# DMPAC0_SDE_0_PAR_PAR_SDE_S_VBUSP_MEM_MMRRAM_VBUSP_MMR_RAM register map
Vendor: Texas Instruments
Peripheral module from a debugger description file (folder J721S2).
Registers are 32-bit, read-only, reset 0x0 unless marked. A register's access mark holds for its fields unless they carry their own. Offsets are as the file gives them; lines under a group give offsets from that group; [hi:lo] are bit positions; {n}, {i} and the like mark numbered series; 'fields as' and 'values as' point back to an identical list; <NAME> marks a mode.

## DMPAC0_SDE_0_PAR_PAR_SDE_S_VBUSP_MEM_MMRRAM_VBUSP_MMR_RAM
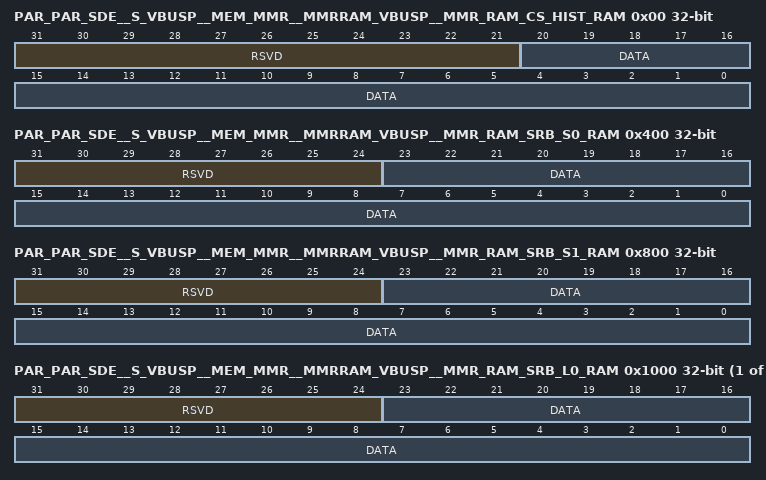
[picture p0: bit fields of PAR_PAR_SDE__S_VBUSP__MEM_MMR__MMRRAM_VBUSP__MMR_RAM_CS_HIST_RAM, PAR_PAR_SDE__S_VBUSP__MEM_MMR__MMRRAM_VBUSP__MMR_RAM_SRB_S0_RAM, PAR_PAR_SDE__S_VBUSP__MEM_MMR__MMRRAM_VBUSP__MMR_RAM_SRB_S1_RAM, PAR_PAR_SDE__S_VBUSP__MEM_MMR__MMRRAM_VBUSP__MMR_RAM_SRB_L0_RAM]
0x00 PAR_PAR_SDE__S_VBUSP__MEM_MMR__MMRRAM_VBUSP__MMR_RAM_CS_HIST_RAM — cs_hist_ram diagnostic read only port, vbusp will stall until RAM is available for read
  [31:21] RSVD — Always read as 0. Writes have no effect.
  [20:0] DATA — Data read from RAM
0x400 PAR_PAR_SDE__S_VBUSP__MEM_MMR__MMRRAM_VBUSP__MMR_RAM_SRB_S0_RAM — srb_s0_ram diagnostic read only port, vbusp will stall until RAM is available for read
  [31:24] RSVD — Always read as 0. Writes have no effect.
  [23:0] DATA — Data read from RAM
0x800 PAR_PAR_SDE__S_VBUSP__MEM_MMR__MMRRAM_VBUSP__MMR_RAM_SRB_S1_RAM — srb_s1_ram diagnostic read only port, vbusp will stall until RAM is available for read
  fields as PAR_PAR_SDE__S_VBUSP__MEM_MMR__MMRRAM_VBUSP__MMR_RAM_SRB_S0_RAM
{0x1000+0x800*i} PAR_PAR_SDE__S_VBUSP__MEM_MMR__MMRRAM_VBUSP__MMR_RAM_SRB_L{i}_RAM (i=0..6) — srb_l{i}_ram diagnostic read only port, vbusp will stall until RAM is available for read
  fields as PAR_PAR_SDE__S_VBUSP__MEM_MMR__MMRRAM_VBUSP__MMR_RAM_SRB_S0_RAM
0x6000 PAR_PAR_SDE__S_VBUSP__MEM_MMR__MMRRAM_VBUSP__MMR_RAM_DRCG_FAST_LR_RAM — drcg_fast_lr_ram diagnostic read only port, vbusp will stall until RAM is available for read
  [31:0] DATA — Data read from RAM. RAM is wider than 32bit vbus. MMR reads are byte addresses into RAM where RAM Width is extended/zero padded to next pwr2.
{0x8000+0x4000*i} PAR_PAR_SDE__S_VBUSP__MEM_MMR__MMRRAM_VBUSP__MMR_RAM_LCC_OP{i}_RAM (i=0..4) — lcc_op{i}_ram diagnostic read only port, vbusp will stall until RAM is available for read
  fields as PAR_PAR_SDE__S_VBUSP__MEM_MMR__MMRRAM_VBUSP__MMR_RAM_DRCG_FAST_LR_RAM
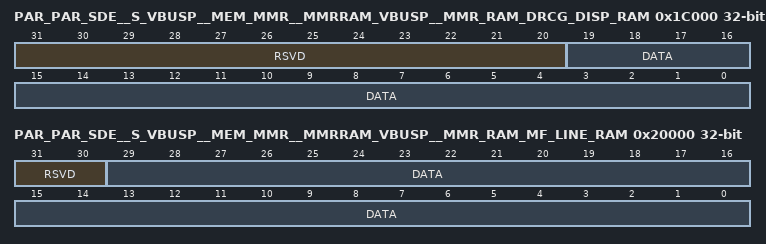
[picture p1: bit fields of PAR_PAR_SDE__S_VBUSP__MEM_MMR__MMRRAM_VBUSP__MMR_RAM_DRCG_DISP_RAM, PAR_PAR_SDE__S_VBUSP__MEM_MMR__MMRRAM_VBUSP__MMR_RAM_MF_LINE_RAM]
0x1C000 PAR_PAR_SDE__S_VBUSP__MEM_MMR__MMRRAM_VBUSP__MMR_RAM_DRCG_DISP_RAM — drcg_disp_ram diagnostic read only port, vbusp will stall until RAM is available for read
  [31:20] RSVD — Always read as 0. Writes have no effect.
  [19:0] DATA — Data read from RAM
0x20000 PAR_PAR_SDE__S_VBUSP__MEM_MMR__MMRRAM_VBUSP__MMR_RAM_MF_LINE_RAM — mf_line_ram diagnostic read only port, vbusp will stall until RAM is available for read
  [31:30] RSVD — Always read as 0. Writes have no effect.
  [29:0] DATA — Data read from RAM
0x28000 PAR_PAR_SDE__S_VBUSP__MEM_MMR__MMRRAM_VBUSP__MMR_RAM_SCA_BRC_RAM — sca_brc_ram diagnostic read only port, vbusp will stall until RAM is available for read
  fields as PAR_PAR_SDE__S_VBUSP__MEM_MMR__MMRRAM_VBUSP__MMR_RAM_DRCG_FAST_LR_RAM
0x30000 PAR_PAR_SDE__S_VBUSP__MEM_MMR__MMRRAM_VBUSP__MMR_RAM_SCA_BPCC_RAM — sca_bpcc_ram diagnostic read only port, vbusp will stall until RAM is available for read
  fields as PAR_PAR_SDE__S_VBUSP__MEM_MMR__MMRRAM_VBUSP__MMR_RAM_DRCG_FAST_LR_RAM
